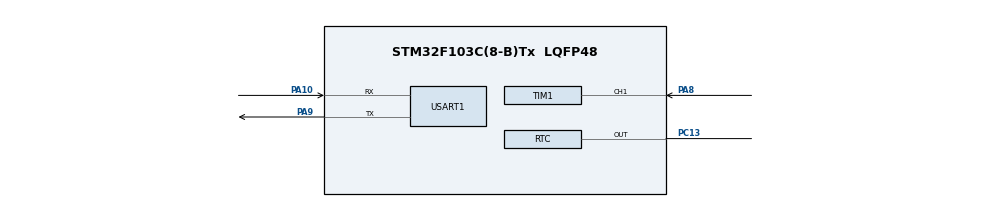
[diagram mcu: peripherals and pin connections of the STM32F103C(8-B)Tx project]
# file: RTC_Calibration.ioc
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Mcu.Family=STM32F1
Mcu.Name=STM32F103C(8-B)Tx
Mcu.Package=LQFP48
NVIC.PriorityGroup=NVIC_PRIORITYGROUP_4
NVIC.TIM1_CC_IRQn=true\:0\:0\:false\:false\:true\:true\:true
PA10.Mode=Asynchronous
PA10.Signal=USART1_RX
PA13.Mode=JTAG_5_pins
PA13.Signal=SYS_JTMS-SWDIO
PA14.Mode=JTAG_5_pins
PA14.Signal=SYS_JTCK-SWCLK
PA15.Mode=JTAG_5_pins
PA15.Signal=SYS_JTDI
PA8.Signal=S_TIM1_CH1
PA9.Mode=Asynchronous
PA9.Signal=USART1_TX
PB3.Mode=JTAG_5_pins
PB3.Signal=SYS_JTDO-TRACESWO
PB4.Mode=JTAG_5_pins
PB4.Signal=SYS_NJTRST
PC13-TAMPER-RTC.Mode=RTC OUT
PC13-TAMPER-RTC.Signal=RTC_OUT
PC14-OSC32_IN.Mode=LSE-External-Oscillator
PC14-OSC32_IN.Signal=RCC_OSC32_IN
PC15-OSC32_OUT.Mode=LSE-External-Oscillator
PC15-OSC32_OUT.Signal=RCC_OSC32_OUT
PD0-OSC_IN.Mode=HSE-External-Oscillator
PD0-OSC_IN.Signal=RCC_OSC_IN
PD1-OSC_OUT.Mode=HSE-External-Oscillator
PD1-OSC_OUT.Signal=RCC_OSC_OUT
ProjectManager.HeapSize=0x200
ProjectManager.StackSize=0x400
ProjectManager.TargetToolchain=MDK-ARM V5.27
RCC.AHBFreq_Value=72000000
RCC.APB1CLKDivider=RCC_HCLK_DIV2
RCC.APB1Freq_Value=36000000
RCC.APB1TimFreq_Value=72000000
RCC.APB2Freq_Value=72000000
RCC.APB2TimFreq_Value=72000000
RCC.HCLKFreq_Value=72000000
RCC.PLLMUL=RCC_PLL_MUL9
RCC.PLLSourceVirtual=RCC_PLLSOURCE_HSE
RCC.RTCClockSelection=RCC_RTCCLKSOURCE_LSE
RCC.SYSCLKFreq_VALUE=72000000
RCC.SYSCLKSource=RCC_SYSCLKSOURCE_PLLCLK
RCC.USBFreq_Value=72000000
SH.S_TIM1_CH1.0=TIM1_CH1,Input_Capture1_from_TI1
TIM1.Channel-Input_Capture1_from_TI1=TIM_CHANNEL_1
TIM1.Prescaler=71
USART1.VirtualMode=VM_ASYNC
VP_RTC_VS_RTC_Activate.Mode=RTC_Enabled
VP_RTC_VS_RTC_Calendar.Mode=RTC_Calendar
VP_TIM1_VS_ClockSourceINT.Mode=Internal
board=custom

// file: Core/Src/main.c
/* USER CODE BEGIN Header */
/**
  ******************************************************************************
  * @file           : main.c
  * @brief          : Main program body
  ******************************************************************************
  * @attention
  *
  * <h2><center>&copy; Copyright (c) 2021 STMicroelectronics.
  * All rights reserved.</center></h2>
  *
  * This software component is licensed by ST under BSD 3-Clause license,
  * the "License"; You may not use this file except in compliance with the
  * License. You may obtain a copy of the License at:
  *                        opensource.org/licenses/BSD-3-Clause
  *
  ******************************************************************************
  */
/* USER CODE END Header */
#include "main.h"

/* USER CODE BEGIN Includes */
#include "RTC_Date&Time.h"
#include "stdio_usart1.h"
/* USER CODE END Includes */

void SystemClock_Config(void);
static void MX_GPIO_Init(void);
static void MX_RTC_Init(void);
static void MX_TIM1_Init(void);
static void MX_USART1_UART_Init(void);

int main(void)
{

  /* MCU Configuration--------------------------------------------------------*/

  /* Reset of all peripherals, Initializes the Flash interface and the Systick. */

  LL_APB2_GRP1_EnableClock(LL_APB2_GRP1_PERIPH_AFIO);
  LL_APB1_GRP1_EnableClock(LL_APB1_GRP1_PERIPH_PWR);

  NVIC_SetPriorityGrouping(NVIC_PRIORITYGROUP_4);

  /* System interrupt init*/

  /** ENABLE: Full SWJ (JTAG-DP + SW-DP): Reset State
  */
  LL_GPIO_AF_EnableRemap_SWJ();

  /* Configure the system clock */
  SystemClock_Config();

  /* Initialize all configured peripherals */
  MX_GPIO_Init();
  MX_RTC_Init();
  MX_TIM1_Init();
  MX_USART1_UART_Init();
  /* USER CODE BEGIN 2 */
//	RTC_SetPrescaler(0xFFFD);
	RTC_SettingBegin(false);																		// since we dont need alarm interrupt the input is false
	DATE_Config(12, 13, 2021); 																	// configuring date
	TIME_Config(23, 59, 56); 																		// configuring time
	RTC_SettingEnd();

	// enabling timer1 and activating input capture mode
  LL_TIM_CC_EnableChannel(TIM1, LL_TIM_CHANNEL_CH1);
  LL_TIM_EnableCounter(TIM1);
	LL_RTC_SetOutputSource(BKP, LL_RTC_CALIB_OUTPUT_RTCCLOCK);
  /* USER CODE END 2 */

  /* Infinite loop */
  while (1)
  {

    /* USER CODE BEGIN 3 */
		Show_Date_and_Time();
  }
  /* USER CODE END 3 */
}

void SystemClock_Config(void)
{
  LL_FLASH_SetLatency(LL_FLASH_LATENCY_2);
  while(LL_FLASH_GetLatency()!= LL_FLASH_LATENCY_2)
  {
  }
  LL_RCC_HSE_Enable();

   /* Wait till HSE is ready */
  while(LL_RCC_HSE_IsReady() != 1)
  {

  }
  LL_PWR_EnableBkUpAccess();
  LL_RCC_LSE_Enable();

   /* Wait till LSE is ready */
  while(LL_RCC_LSE_IsReady() != 1)
  {

  }
  if(LL_RCC_GetRTCClockSource() != LL_RCC_RTC_CLKSOURCE_LSE)
  {
    LL_RCC_ForceBackupDomainReset();
    LL_RCC_ReleaseBackupDomainReset();
    LL_RCC_SetRTCClockSource(LL_RCC_RTC_CLKSOURCE_LSE);
  }
  LL_RCC_EnableRTC();
  LL_RCC_PLL_ConfigDomain_SYS(LL_RCC_PLLSOURCE_HSE_DIV_1, LL_RCC_PLL_MUL_9);
  LL_RCC_PLL_Enable();

   /* Wait till PLL is ready */
  while(LL_RCC_PLL_IsReady() != 1)
  {

  }
  LL_RCC_SetAHBPrescaler(LL_RCC_SYSCLK_DIV_1);
  LL_RCC_SetAPB1Prescaler(LL_RCC_APB1_DIV_2);
  LL_RCC_SetAPB2Prescaler(LL_RCC_APB2_DIV_1);
  LL_RCC_SetSysClkSource(LL_RCC_SYS_CLKSOURCE_PLL);

   /* Wait till System clock is ready */
  while(LL_RCC_GetSysClkSource() != LL_RCC_SYS_CLKSOURCE_STATUS_PLL)
  {

  }
  LL_Init1msTick(72000000);
  LL_SetSystemCoreClock(72000000);
}

static void MX_RTC_Init(void)
{

  LL_RTC_InitTypeDef RTC_InitStruct = {0};
  LL_RTC_TimeTypeDef RTC_TimeStruct = {0};
  LL_RTC_AlarmTypeDef RTC_AlarmStruct = {0};

    LL_PWR_EnableBkUpAccess();
    /* Enable BKP CLK enable for backup registers */
    LL_APB1_GRP1_EnableClock(LL_APB1_GRP1_PERIPH_BKP);
  /* Peripheral clock enable */
  LL_RCC_EnableRTC();

  /** Initialize RTC and set the Time and Date
  */
  RTC_InitStruct.AsynchPrescaler = 0xFFFFFFFFU;
  LL_RTC_Init(RTC, &RTC_InitStruct);
  LL_RTC_SetAsynchPrescaler(RTC, 0xFFFFFFFFU);
  /** Initialize RTC and set the Time and Date
  */
  RTC_TimeStruct.Hours = 0;
  RTC_TimeStruct.Minutes = 0;
  RTC_TimeStruct.Seconds = 0;
  LL_RTC_TIME_Init(RTC, LL_RTC_FORMAT_BCD, &RTC_TimeStruct);
  /** Initialize RTC and set the Time and Date
  */
  /** Enable the Alarm A
  */
  RTC_AlarmStruct.AlarmTime.Hours = 0x0;
  RTC_AlarmStruct.AlarmTime.Minutes = 0x0;
  RTC_AlarmStruct.AlarmTime.Seconds = 0x0;
  LL_RTC_ALARM_Init(RTC, LL_RTC_FORMAT_BCD, &RTC_AlarmStruct);
  /* USER CODE BEGIN RTC_Init 2 */
  RTC_InitStruct.AsynchPrescaler = 0x00007FFDU;
  LL_RTC_Init(RTC, &RTC_InitStruct);
  LL_RTC_SetAsynchPrescaler(RTC, 0x00007FFDU);
  /* USER CODE END RTC_Init 2 */

}

static void MX_TIM1_Init(void)
{

  LL_TIM_InitTypeDef TIM_InitStruct = {0};

  LL_GPIO_InitTypeDef GPIO_InitStruct = {0};

  /* Peripheral clock enable */
  LL_APB2_GRP1_EnableClock(LL_APB2_GRP1_PERIPH_TIM1);

  LL_APB2_GRP1_EnableClock(LL_APB2_GRP1_PERIPH_GPIOA);
  /**TIM1 GPIO Configuration
  PA8   ------> TIM1_CH1
  */
  GPIO_InitStruct.Pin = LL_GPIO_PIN_8;
  GPIO_InitStruct.Mode = LL_GPIO_MODE_FLOATING;
  LL_GPIO_Init(GPIOA, &GPIO_InitStruct);

  /* TIM1 interrupt Init */
  NVIC_SetPriority(TIM1_CC_IRQn, NVIC_EncodePriority(NVIC_GetPriorityGrouping(),0, 0));
  NVIC_EnableIRQ(TIM1_CC_IRQn);

  TIM_InitStruct.Prescaler = 71;
  TIM_InitStruct.CounterMode = LL_TIM_COUNTERMODE_UP;
  TIM_InitStruct.Autoreload = 65535;
  TIM_InitStruct.ClockDivision = LL_TIM_CLOCKDIVISION_DIV1;
  TIM_InitStruct.RepetitionCounter = 0;
  LL_TIM_Init(TIM1, &TIM_InitStruct);
  LL_TIM_DisableARRPreload(TIM1);
  LL_TIM_SetClockSource(TIM1, LL_TIM_CLOCKSOURCE_INTERNAL);
  LL_TIM_SetTriggerOutput(TIM1, LL_TIM_TRGO_RESET);
  LL_TIM_DisableMasterSlaveMode(TIM1);
  LL_TIM_IC_SetActiveInput(TIM1, LL_TIM_CHANNEL_CH1, LL_TIM_ACTIVEINPUT_DIRECTTI);
  LL_TIM_IC_SetPrescaler(TIM1, LL_TIM_CHANNEL_CH1, LL_TIM_ICPSC_DIV1);
  LL_TIM_IC_SetFilter(TIM1, LL_TIM_CHANNEL_CH1, LL_TIM_IC_FILTER_FDIV1);
  LL_TIM_IC_SetPolarity(TIM1, LL_TIM_CHANNEL_CH1, LL_TIM_IC_POLARITY_RISING);

}

static void MX_USART1_UART_Init(void)
{

  LL_USART_InitTypeDef USART_InitStruct = {0};

  LL_GPIO_InitTypeDef GPIO_InitStruct = {0};

  /* Peripheral clock enable */
  LL_APB2_GRP1_EnableClock(LL_APB2_GRP1_PERIPH_USART1);

  LL_APB2_GRP1_EnableClock(LL_APB2_GRP1_PERIPH_GPIOA);
  /**USART1 GPIO Configuration
  PA9   ------> USART1_TX
  PA10   ------> USART1_RX
  */
  GPIO_InitStruct.Pin = LL_GPIO_PIN_9;
  GPIO_InitStruct.Mode = LL_GPIO_MODE_ALTERNATE;
  GPIO_InitStruct.Speed = LL_GPIO_SPEED_FREQ_HIGH;
  GPIO_InitStruct.OutputType = LL_GPIO_OUTPUT_PUSHPULL;
  LL_GPIO_Init(GPIOA, &GPIO_InitStruct);

  GPIO_InitStruct.Pin = LL_GPIO_PIN_10;
  GPIO_InitStruct.Mode = LL_GPIO_MODE_FLOATING;
  LL_GPIO_Init(GPIOA, &GPIO_InitStruct);

  USART_InitStruct.BaudRate = 115200;
  USART_InitStruct.DataWidth = LL_USART_DATAWIDTH_8B;
  USART_InitStruct.StopBits = LL_USART_STOPBITS_1;
  USART_InitStruct.Parity = LL_USART_PARITY_NONE;
  USART_InitStruct.TransferDirection = LL_USART_DIRECTION_TX_RX;
  USART_InitStruct.HardwareFlowControl = LL_USART_HWCONTROL_NONE;
  USART_InitStruct.OverSampling = LL_USART_OVERSAMPLING_16;
  LL_USART_Init(USART1, &USART_InitStruct);
  LL_USART_ConfigAsyncMode(USART1);
  LL_USART_Enable(USART1);

}

static void MX_GPIO_Init(void)
{

  /* GPIO Ports Clock Enable */
  LL_APB2_GRP1_EnableClock(LL_APB2_GRP1_PERIPH_GPIOC);
  LL_APB2_GRP1_EnableClock(LL_APB2_GRP1_PERIPH_GPIOD);
  LL_APB2_GRP1_EnableClock(LL_APB2_GRP1_PERIPH_GPIOA);
  LL_APB2_GRP1_EnableClock(LL_APB2_GRP1_PERIPH_GPIOB);

}

void Error_Handler(void)
{
  __disable_irq();
  while (1)
  {
  }
}

/************************ (C) COPYRIGHT STMicroelectronics *****END OF FILE****/
